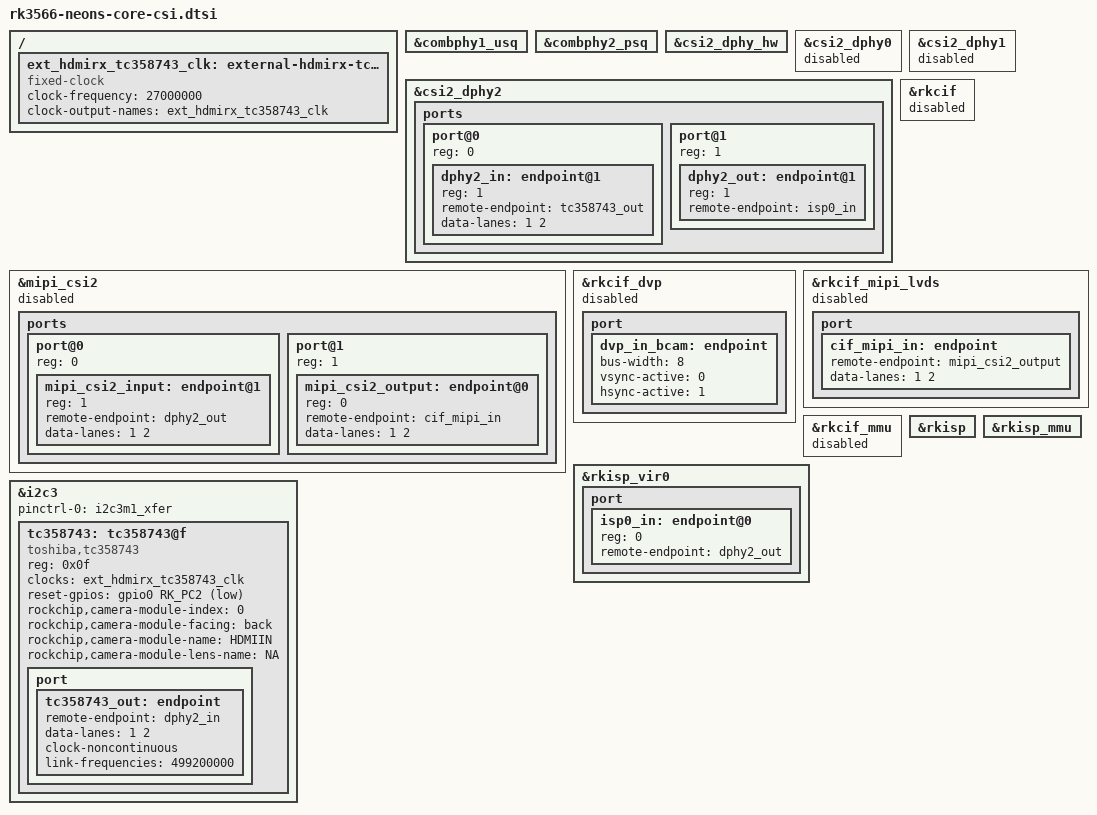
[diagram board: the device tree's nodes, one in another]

/ {
	ext_hdmirx_tc358743_clk: external-hdmirx-tc358743-clock {
		compatible = "fixed-clock";
		clock-frequency = <27000000>;
		clock-output-names = "ext_hdmirx_tc358743_clk";
		#clock-cells = <0>;
	};
};

//phy u序列
&combphy1_usq {
	status = "okay";
};

//phy P序列
&combphy2_psq {
	status = "okay";
};

//dphy硬件
&csi2_dphy_hw {
	status = "okay";
};

//摄像头D-PHY接口
&csi2_dphy0 {
	status = "disabled";
	/*
	 * dphy0 only used for full mode,
	 * full mode and split mode are mutually exclusive
	 */
};

//摄像头D-PHY接口
&csi2_dphy1 {
	status = "disabled";
	/*
	 * dphy1 only used for split mode,
	 * can be used  concurrently  with dphy2
	 * full mode and split mode are mutually exclusive
	 */
};
//摄像头D-PHY接口
&csi2_dphy2 {
	status = "okay";

	/*
	 * dphy2 only used for split mode,
	 * can be used  concurrently  with dphy1
	 * full mode and split mode are mutually exclusive
	 */
	ports {
		#address-cells = <1>;
		#size-cells = <0>;

		port@0 {
			reg = <0>;
			#address-cells = <1>;
			#size-cells = <0>;

			dphy2_in: endpoint@1 {
				reg = <1>;
				remote-endpoint = <&tc358743_out>;
				data-lanes = <1 2>;
			};
		};

		port@1 {
			reg = <1>;
			#address-cells = <1>;
			#size-cells = <0>;

			dphy2_out: endpoint@1 {
				reg = <1>;
				remote-endpoint = <&isp0_in>;
			};
		};
	};
};



&mipi_csi2 {
	status = "disabled";

	ports {
		#address-cells = <1>;
		#size-cells = <0>;

		port@0 {
			reg = <0>;
			#address-cells = <1>;
			#size-cells = <0>;

			mipi_csi2_input: endpoint@1 {
				reg = <1>;
				remote-endpoint = <&dphy2_out>;
				data-lanes = <1 2>;
			};
		};

		port@1 {
			reg = <1>;
			#address-cells = <1>;
			#size-cells = <0>;

			mipi_csi2_output: endpoint@0 {
				reg = <0>;
				remote-endpoint = <&cif_mipi_in>;
				data-lanes = <1 2>;
			};
		};
	};
};

//Rockchip Camera Interface
&rkcif {
	status = "disabled";
};

//dvp接口摄像头
&rkcif_dvp {
	status = "disabled";

	port {
		/* Parallel bus endpoint */
		dvp_in_bcam: endpoint {
			// remote-endpoint = <&gc2145_out>;
			bus-width = <8>;
			vsync-active = <0>;
			hsync-active = <1>;
		};
	};
};

//LVDS接口摄像头
&rkcif_mipi_lvds {
	status = "disabled";

	port {
		cif_mipi_in: endpoint {
			remote-endpoint = <&mipi_csi2_output>;
			data-lanes = <1 2>;
		};
	};
};

//摄像头内存管理
&rkcif_mmu {
	status = "disabled";
};

//硬件图像处理器模块
&rkisp {
	status = "okay";
};

//硬件图像处理器模块内存管理器
&rkisp_mmu {
	status = "okay";
};

//图像处理接口
&rkisp_vir0 {
	status = "okay";

	port {
		#address-cells = <1>;
		#size-cells = <0>;

		isp0_in: endpoint@0 {
			reg = <0>;
			remote-endpoint = <&dphy2_out>;
		};
	};
};

&i2c3 {
	status = "okay";
	pinctrl-names = "default";
	pinctrl-0 = <&i2c3m1_xfer>;
	
	tc358743: tc358743@f {
		status = "okay";
		compatible = "toshiba,tc358743";
		reg = <0x0f>;
		clocks = <&ext_hdmirx_tc358743_clk>;
		clock-names = "refclk";
		reset-gpios = <&gpio0 RK_PC2 GPIO_ACTIVE_LOW>;

		rockchip,camera-module-index = <0>;
		rockchip,camera-module-facing = "back";
		rockchip,camera-module-name = "HDMIIN";
		rockchip,camera-module-lens-name = "NA";

		port {
			tc358743_out: endpoint {
				remote-endpoint = <&dphy2_in>;
				data-lanes = <1 2>;
				clock-noncontinuous;
				link-frequencies = /bits/ 64 <499200000>;
			};
		};
	};
};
